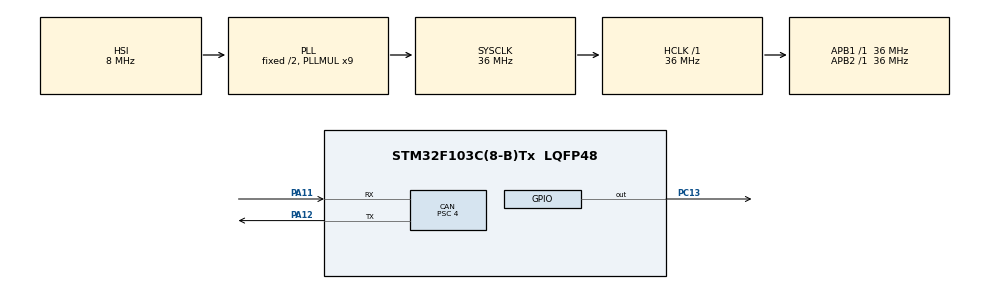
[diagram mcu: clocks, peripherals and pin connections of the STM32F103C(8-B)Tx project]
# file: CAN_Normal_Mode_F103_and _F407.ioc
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CAN.BS1=CAN_BS1_12TQ
CAN.BS2=CAN_BS2_3TQ
CAN.CalculateBaudRate=562500
CAN.CalculateTimeBit=1777
CAN.CalculateTimeQuantum=111.11111111111111
CAN.Mode=CAN_MODE_NORMAL
CAN.Prescaler=4
Mcu.Family=STM32F1
Mcu.Name=STM32F103C(8-B)Tx
Mcu.Package=LQFP48
NVIC.PriorityGroup=NVIC_PRIORITYGROUP_4
PA11.Mode=CAN_Activate
PA11.Signal=CAN_RX
PA12.Mode=CAN_Activate
PA12.Signal=CAN_TX
PA13.Mode=Serial_Wire
PA13.Signal=SYS_JTMS-SWDIO
PA14.Mode=Serial_Wire
PA14.Signal=SYS_JTCK-SWCLK
PC13-TAMPER-RTC.Signal=GPIO_Output
PD0-OSC_IN.Mode=HSE-External-Clock-Source
PD0-OSC_IN.Signal=RCC_OSC_IN
PD1-OSC_OUT.Mode=HSE-External-Clock-Source
PD1-OSC_OUT.Signal=RCC_OSC_OUT
ProjectManager.HeapSize=0x200
ProjectManager.StackSize=0x400
ProjectManager.TargetToolchain=STM32CubeIDE
RCC.AHBFreq_Value=36000000
RCC.APB1Freq_Value=36000000
RCC.APB1TimFreq_Value=36000000
RCC.APB2Freq_Value=36000000
RCC.APB2TimFreq_Value=36000000
RCC.HCLKFreq_Value=36000000
RCC.PLLMUL=RCC_PLL_MUL9
RCC.SYSCLKFreq_VALUE=36000000
RCC.SYSCLKSource=RCC_SYSCLKSOURCE_PLLCLK
RCC.USBFreq_Value=36000000
board=custom

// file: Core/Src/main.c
/* USER CODE BEGIN Header */
/**
  ******************************************************************************
  * @file           : main.c
  * @brief          : Main program body
  ******************************************************************************
  * @attention
  *
  * Copyright (c) 2024 STMicroelectronics.
  * All rights reserved.
  *
  * This software is licensed under terms that can be found in the LICENSE file
  * in the root directory of this software component.
  * If no LICENSE file comes with this software, it is provided AS-IS.
  *
  ******************************************************************************
  */
/* USER CODE END Header */
#include "main.h"

CAN_HandleTypeDef hcan;

/* USER CODE BEGIN PV */

CAN_TxHeaderTypeDef txHeader;  // Declare transmit header
uint32_t txMailbox;             // Transmit mailbox
uint8_t txData[1] = { 'a' };  // Data to send
CAN_RxHeaderTypeDef RxHeader;
uint8_t RxData[1];

/* USER CODE END PV */

void SystemClock_Config(void);
static void MX_GPIO_Init(void);
static void MX_CAN_Init(void);

int main(void)
{

  /* MCU Configuration--------------------------------------------------------*/

  /* Reset of all peripherals, Initializes the Flash interface and the Systick. */
  HAL_Init();

  /* Configure the system clock */
  SystemClock_Config();

  /* Initialize all configured peripherals */
  MX_GPIO_Init();
  MX_CAN_Init();
  /* USER CODE BEGIN 2 */

  CAN_FilterTypeDef canFilterConfig;
       canFilterConfig.FilterBank = 0;
       canFilterConfig.FilterMode = CAN_FILTERMODE_IDMASK;
       canFilterConfig.FilterScale = CAN_FILTERSCALE_32BIT;
       canFilterConfig.FilterIdHigh = 0x0000;
       canFilterConfig.FilterIdLow = 0x0000;
       canFilterConfig.FilterMaskIdHigh = 0x0000;
       canFilterConfig.FilterMaskIdLow = 0x0000;
       canFilterConfig.FilterFIFOAssignment = CAN_RX_FIFO0;
       canFilterConfig.FilterActivation = ENABLE;
       canFilterConfig.SlaveStartFilterBank = 14;

       // Initialize Tx Header (optional)
           txHeader.DLC = 1;  // Data length code: 1 byte
           txHeader.IDE = CAN_ID_STD;  // Standard identifier
           txHeader.StdId = 0x124;  // Identifier
           txHeader.RTR = CAN_RTR_DATA;  // Data frame

  if (HAL_CAN_ConfigFilter(&hcan, &canFilterConfig) != HAL_OK)
         {
           // Filter configuration Error
           Error_Handler();
         }

         // Start CAN
         if (HAL_CAN_Start(&hcan) != HAL_OK)
         {
           // Start Error
           Error_Handler();
         }

         // Activate the notification for message reception
         if (HAL_CAN_ActivateNotification(&hcan, CAN_IT_RX_FIFO0_MSG_PENDING) != HAL_OK)
         {
           // Notification Error
           Error_Handler();
         }

  /* USER CODE END 2 */

  /* Infinite loop */
  /* USER CODE BEGIN WHILE */
  while (1)
  {
   	 //HAL_GPIO_WritePin(GPIOC, GPIO_PIN_13, 1);

    /* USER CODE END WHILE */

    /* USER CODE BEGIN 3 */
//	  if (HAL_CAN_GetTxMailboxesFreeLevel(&hcan) > 0) {
//	  		            if (HAL_CAN_AddTxMessage(&hcan, &txHeader, txData, &txMailbox) != HAL_OK) {
//	  		                Error_Handler();
//	  		            }
//	  		        }
	  		// Check if a CAN message is received
//	  		    if (HAL_CAN_GetRxFifoFillLevel(&hcan, CAN_RX_FIFO0) > 0)
//	  		    {
	  		    	HAL_CAN_GetRxMessage(&hcan, CAN_RX_FIFO0, &RxHeader, RxData);
	  		    	if(RxData[0] == 'V')
	  		    	{
	  		    	   	 HAL_GPIO_WritePin(GPIOC, GPIO_PIN_13, 0);

	  		    	}
	  		    	else if (RxData[0] == 'Y')
	  		    	{

	  		    	   	 HAL_GPIO_WritePin(GPIOC, GPIO_PIN_13, 1);

	  		    	}
//	  		    }else{
//	  		    	Error_Handler();
//	  		    }

	  		   // HAL_Delay(500);
  }
  /* USER CODE END 3 */
}

void SystemClock_Config(void)
{
  RCC_OscInitTypeDef RCC_OscInitStruct = {0};
  RCC_ClkInitTypeDef RCC_ClkInitStruct = {0};

  /** Initializes the RCC Oscillators according to the specified parameters
  * in the RCC_OscInitTypeDef structure.
  */
  RCC_OscInitStruct.OscillatorType = RCC_OSCILLATORTYPE_HSI;
  RCC_OscInitStruct.HSIState = RCC_HSI_ON;
  RCC_OscInitStruct.HSICalibrationValue = RCC_HSICALIBRATION_DEFAULT;
  RCC_OscInitStruct.PLL.PLLState = RCC_PLL_ON;
  RCC_OscInitStruct.PLL.PLLSource = RCC_PLLSOURCE_HSI_DIV2;
  RCC_OscInitStruct.PLL.PLLMUL = RCC_PLL_MUL9;
  if (HAL_RCC_OscConfig(&RCC_OscInitStruct) != HAL_OK)
  {
    Error_Handler();
  }

  /** Initializes the CPU, AHB and APB buses clocks
  */
  RCC_ClkInitStruct.ClockType = RCC_CLOCKTYPE_HCLK|RCC_CLOCKTYPE_SYSCLK
                              |RCC_CLOCKTYPE_PCLK1|RCC_CLOCKTYPE_PCLK2;
  RCC_ClkInitStruct.SYSCLKSource = RCC_SYSCLKSOURCE_PLLCLK;
  RCC_ClkInitStruct.AHBCLKDivider = RCC_SYSCLK_DIV1;
  RCC_ClkInitStruct.APB1CLKDivider = RCC_HCLK_DIV1;
  RCC_ClkInitStruct.APB2CLKDivider = RCC_HCLK_DIV1;

  if (HAL_RCC_ClockConfig(&RCC_ClkInitStruct, FLASH_LATENCY_1) != HAL_OK)
  {
    Error_Handler();
  }
}

static void MX_CAN_Init(void)
{

  hcan.Instance = CAN1;
  hcan.Init.Prescaler = 4;
  hcan.Init.Mode = CAN_MODE_NORMAL;
  hcan.Init.SyncJumpWidth = CAN_SJW_1TQ;
  hcan.Init.TimeSeg1 = CAN_BS1_12TQ;
  hcan.Init.TimeSeg2 = CAN_BS2_3TQ;
  hcan.Init.TimeTriggeredMode = DISABLE;
  hcan.Init.AutoBusOff = DISABLE;
  hcan.Init.AutoWakeUp = DISABLE;
  hcan.Init.AutoRetransmission = DISABLE;
  hcan.Init.ReceiveFifoLocked = DISABLE;
  hcan.Init.TransmitFifoPriority = DISABLE;
  if (HAL_CAN_Init(&hcan) != HAL_OK)
  {
    Error_Handler();
  }

}

static void MX_GPIO_Init(void)
{
  GPIO_InitTypeDef GPIO_InitStruct = {0};

  /* GPIO Ports Clock Enable */
  __HAL_RCC_GPIOC_CLK_ENABLE();
  __HAL_RCC_GPIOD_CLK_ENABLE();
  __HAL_RCC_GPIOA_CLK_ENABLE();

  /*Configure GPIO pin Output Level */
  HAL_GPIO_WritePin(GPIOC, GPIO_PIN_13, GPIO_PIN_RESET);

  /*Configure GPIO pin : PC13 */
  GPIO_InitStruct.Pin = GPIO_PIN_13;
  GPIO_InitStruct.Mode = GPIO_MODE_OUTPUT_PP;
  GPIO_InitStruct.Pull = GPIO_NOPULL;
  GPIO_InitStruct.Speed = GPIO_SPEED_FREQ_LOW;
  HAL_GPIO_Init(GPIOC, &GPIO_InitStruct);

}

void Error_Handler(void)
{
  __disable_irq();
  while (1)
  {
  }
}
